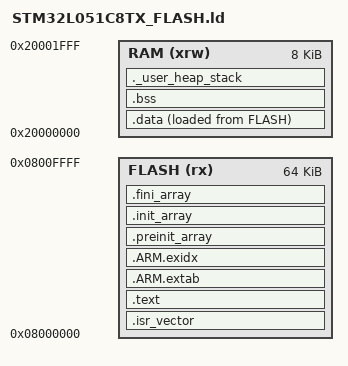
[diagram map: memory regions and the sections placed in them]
ENTRY(Reset_Handler)

MEMORY
{
  FLASH (rx)  : ORIGIN = 0x08000000, LENGTH = 64K
  RAM   (xrw) : ORIGIN = 0x20000000, LENGTH = 8K
}

_estack = ORIGIN(RAM) + LENGTH(RAM);
_Min_Heap_Size = 0;
_Min_Stack_Size = 0x800;

SECTIONS
{
  .isr_vector : { KEEP(*(.isr_vector)) } > FLASH
  .text :
  {
    . = ALIGN(4);
    *(.text*) *(.rodata*)
    KEEP(*(.init)) KEEP(*(.fini))
    . = ALIGN(4);
    _etext = .;
  } > FLASH
  .ARM.extab : { *(.ARM.extab*) } > FLASH
  .ARM.exidx : { *(.ARM.exidx*) } > FLASH
  .preinit_array : { KEEP(*(.preinit_array*)) } > FLASH
  .init_array : { KEEP(*(.init_array*)) } > FLASH
  .fini_array : { KEEP(*(.fini_array*)) } > FLASH

  .data :
  {
    . = ALIGN(4);
    _sdata = .;
    *(.data*)
    . = ALIGN(4);
    _edata = .;
  } > RAM AT> FLASH
  _sidata = LOADADDR(.data);

  .bss (NOLOAD) :
  {
    . = ALIGN(4);
    _sbss = .;
    *(.bss*) *(COMMON)
    . = ALIGN(4);
    _ebss = .;
  } > RAM

  ._user_heap_stack (NOLOAD) :
  {
    . = ALIGN(8);
    . += _Min_Heap_Size;
    . += _Min_Stack_Size;
    . = ALIGN(8);
  } > RAM

  /DISCARD/ : { *(.comment*) *(.note*) }
}
